VERSION "colliding-dbcs modern 2.0"

NS_ :

BS_:

BU_: VCU GW

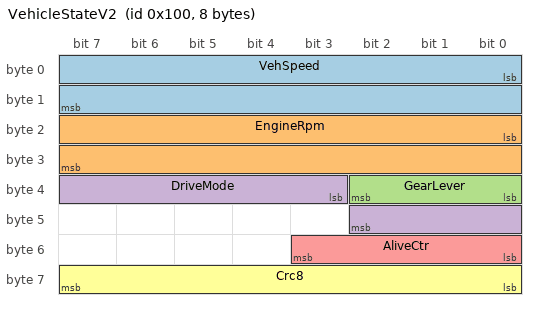
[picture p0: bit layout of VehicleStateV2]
BO_ 256 VehicleStateV2: 8 VCU
 SG_ VehSpeed : 0|16@1+ (0.00621371,0) [0|407.19] "mph" GW
 SG_ EngineRpm : 16|16@1+ (0.25,0) [0|16383.75] "rpm" GW
 SG_ GearLever : 32|3@1+ (1,0) [0|7] "" GW
 SG_ DriveMode : 35|8@1+ (1,0) [0|255] "" GW
 SG_ AliveCtr : 48|4@1+ (1,0) [0|15] "" GW
 SG_ Crc8 : 56|8@1+ (1,0) [0|255] "" GW

BO_ 258 ModernOnly: 4 VCU
 SG_ ModernHeartbeat : 0|8@1+ (1,0) [0|255] "" GW

CM_ BO_ 256 "The same arbitration id under a new name, a new scale and a new vocabulary.";
CM_ SG_ 256 VehSpeed "Imperial. Same wire bits as the outgoing database's km/h.";
CM_ SG_ 256 DriveMode "Occupies the bits the outgoing database calls BrakePedal.";

BA_DEF_ BO_ "GenMsgCycleTime" INT 0 100000;
BA_DEF_ SG_ "CannetCounter" STRING ;
BA_DEF_ SG_ "CannetCrc" STRING ;
BA_DEF_DEF_ "GenMsgCycleTime" 0;
BA_DEF_DEF_ "CannetCounter" "";
BA_DEF_DEF_ "CannetCrc" "";
BA_ "GenMsgCycleTime" BO_ 256 50;
BA_ "CannetCounter" SG_ 256 AliveCtr "increment=1;rollover=15";
BA_ "CannetCrc" SG_ 256 Crc8 "alg=CRC-8/SAE-J1850;range=0:56;prefix=A3";

VAL_ 256 GearLever 0 "Park" 1 "Reverse" 2 "Neutral" 3 "Drive" 4 "Sport" 5 "Low" 6 "Manual" 7 "Undefined";
